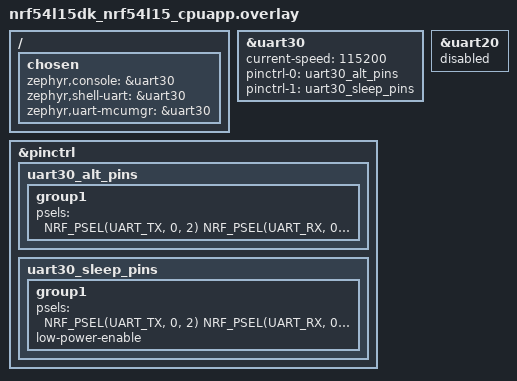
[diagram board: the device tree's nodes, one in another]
//changing uart port to uart0 //pj_change
/ {
    chosen {
        zephyr,console = &uart30;
        zephyr,shell-uart = &uart30;
        zephyr,uart-mcumgr = &uart30;
    };
};
/* UART30 configuration */
&uart30 {
    status = "okay";
    current-speed = <115200>;
    pinctrl-names = "default", "sleep";
    pinctrl-0 = <&uart30_alt_pins>;
    pinctrl-1 = <&uart30_sleep_pins>;
};
/* UART30 pin mapping */
&pinctrl {
    uart30_alt_pins: uart30_alt_pins {
        group1 {
            psels = <
                NRF_PSEL(UART_TX, 0, 2)
                NRF_PSEL(UART_RX, 0, 3)
                NRF_PSEL(UART_RTS, 0, 0)
                NRF_PSEL(UART_CTS, 0, 1)
            >;
        };
    };
    uart30_sleep_pins: uart30_sleep_pins {
        group1 {
            /* All pins disabled in sleep state */
            psels = <
                NRF_PSEL(UART_TX, 0, 2)
                NRF_PSEL(UART_RX, 0, 3)
                NRF_PSEL(UART_RTS, 0, 0)
                NRF_PSEL(UART_CTS, 0, 1)
            >;
            low-power-enable;
        };
    };
};

&uart20 {
    status = "disabled";
};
